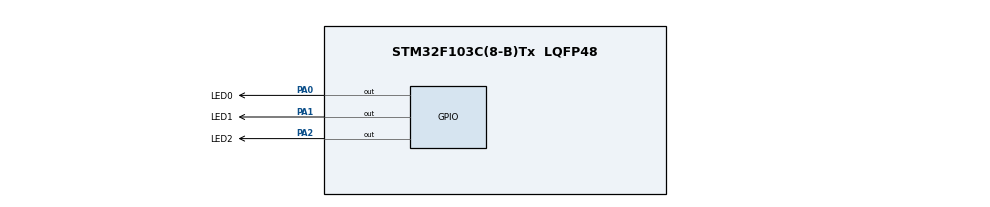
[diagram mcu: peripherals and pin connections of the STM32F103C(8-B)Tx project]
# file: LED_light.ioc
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Mcu.Family=STM32F1
Mcu.Name=STM32F103C(8-B)Tx
Mcu.Package=LQFP48
NVIC.PriorityGroup=NVIC_PRIORITYGROUP_4
PA0-WKUP.GPIO_Label=LED0
PA0-WKUP.Signal=GPIO_Output
PA1.GPIO_Label=LED1
PA1.Signal=GPIO_Output
PA13.Mode=Serial_Wire
PA13.Signal=SYS_JTMS-SWDIO
PA14.Mode=Serial_Wire
PA14.Signal=SYS_JTCK-SWCLK
PA2.GPIO_Label=LED2
PA2.Signal=GPIO_Output
PD0-OSC_IN.Mode=HSE-External-Oscillator
PD0-OSC_IN.Signal=RCC_OSC_IN
PD1-OSC_OUT.Mode=HSE-External-Oscillator
PD1-OSC_OUT.Signal=RCC_OSC_OUT
ProjectManager.HeapSize=0x200
ProjectManager.StackSize=0x400
ProjectManager.TargetToolchain=CMake
RCC.APB1Freq_Value=8000000
RCC.APB2Freq_Value=8000000
board=custom

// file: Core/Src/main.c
/* USER CODE BEGIN Header */
/**
  ******************************************************************************
  * @file           : main.c
  * @brief          : Main program body
  ******************************************************************************
  * @attention
  *
  * Copyright (c) 2026 STMicroelectronics.
  * All rights reserved.
  *
  * This software is licensed under terms that can be found in the LICENSE file
  * in the root directory of this software component.
  * If no LICENSE file comes with this software, it is provided AS-IS.
  *
  ******************************************************************************
  */
/* USER CODE END Header */
#include "main.h"

/* USER CODE BEGIN PD */
#define LED_NUM         3U     /* 三个灯：PA0/PA1/PA2 */
#define LED_DELAY_MS    500U   /* 每步停留 500ms，*/
#define LED_ACTIVE_LOW  1      /* 1=低电平点亮；0=高电平点亮 */
/* USER CODE END PD */

/* USER CODE BEGIN PV */
static const uint16_t      led_pin [LED_NUM] = { LED0_Pin,       LED1_Pin,       LED2_Pin       };
static GPIO_TypeDef *const led_port[LED_NUM] = { LED0_GPIO_Port, LED1_GPIO_Port, LED2_GPIO_Port };

static uint32_t led_last_tick = 0U;
static uint8_t  led_index     = 0U;
/* USER CODE END PV */

void SystemClock_Config(void);
static void MX_GPIO_Init(void);

/* USER CODE BEGIN 0 */
/** @brief 点亮第 idx 个 LED（按 LED_ACTIVE_LOW 自动取电平） */
static void Led_On(uint8_t idx)
{
  HAL_GPIO_WritePin(led_port[idx], led_pin[idx],
                    LED_ACTIVE_LOW ? GPIO_PIN_RESET : GPIO_PIN_SET);
}

/** @brief 熄灭第 idx 个 LED */
static void Led_Off(uint8_t idx)
{
  HAL_GPIO_WritePin(led_port[idx], led_pin[idx],
                    LED_ACTIVE_LOW ? GPIO_PIN_SET : GPIO_PIN_RESET);
}

/** @brief 全部熄灭 */
static void Led_AllOff(void)
{
  for (uint8_t i = 0U; i < LED_NUM; i++)
  {
    Led_Off(i);
  }
}
/* USER CODE END 0 */

int main(void)
{

  /* MCU Configuration--------------------------------------------------------*/

  /* Reset of all peripherals, Initializes the Flash interface and the Systick. */
  HAL_Init();

  /* Configure the system clock */
  SystemClock_Config();

  /* Initialize all configured peripherals */
  MX_GPIO_Init();
  /* USER CODE BEGIN 2 */
  Led_AllOff();

  Led_On(0);                 /* 上电先亮 PA0 */
  led_index     = 1U;        /* 下一个轮到 1 */
  led_last_tick = HAL_GetTick();
  /* USER CODE END 2 */

  /* Infinite loop */
  while (1) {

    /* USER CODE BEGIN 3 */
    for (uint8_t i = 0U; i < LED_NUM; i++)
    {

      if ((HAL_GetTick() - led_last_tick) >= LED_DELAY_MS)
      {
        led_last_tick += LED_DELAY_MS;

        Led_AllOff();
        Led_On(led_index);
        led_index = (uint8_t)((led_index + 1U) % LED_NUM);   /* 0→1→2→0 */
      }

    }
  }
  /* USER CODE END 3 */
}

void SystemClock_Config(void)
{
  RCC_OscInitTypeDef RCC_OscInitStruct = {0};
  RCC_ClkInitTypeDef RCC_ClkInitStruct = {0};

  /** Initializes the RCC Oscillators according to the specified parameters
  * in the RCC_OscInitTypeDef structure.
  */
  RCC_OscInitStruct.OscillatorType = RCC_OSCILLATORTYPE_HSI;
  RCC_OscInitStruct.HSIState = RCC_HSI_ON;
  RCC_OscInitStruct.HSICalibrationValue = RCC_HSICALIBRATION_DEFAULT;
  RCC_OscInitStruct.PLL.PLLState = RCC_PLL_NONE;
  if (HAL_RCC_OscConfig(&RCC_OscInitStruct) != HAL_OK)
  {
    Error_Handler();
  }

  /** Initializes the CPU, AHB and APB buses clocks
  */
  RCC_ClkInitStruct.ClockType = RCC_CLOCKTYPE_HCLK|RCC_CLOCKTYPE_SYSCLK
                              |RCC_CLOCKTYPE_PCLK1|RCC_CLOCKTYPE_PCLK2;
  RCC_ClkInitStruct.SYSCLKSource = RCC_SYSCLKSOURCE_HSI;
  RCC_ClkInitStruct.AHBCLKDivider = RCC_SYSCLK_DIV1;
  RCC_ClkInitStruct.APB1CLKDivider = RCC_HCLK_DIV1;
  RCC_ClkInitStruct.APB2CLKDivider = RCC_HCLK_DIV1;

  if (HAL_RCC_ClockConfig(&RCC_ClkInitStruct, FLASH_LATENCY_0) != HAL_OK)
  {
    Error_Handler();
  }
}

static void MX_GPIO_Init(void)
{
  GPIO_InitTypeDef GPIO_InitStruct = {0};

  /* GPIO Ports Clock Enable */
  __HAL_RCC_GPIOD_CLK_ENABLE();
  __HAL_RCC_GPIOA_CLK_ENABLE();

  /*Configure GPIO pin Output Level */
  HAL_GPIO_WritePin(GPIOA, LED0_Pin|LED1_Pin|LED2_Pin, GPIO_PIN_RESET);

  /*Configure GPIO pins : LED0_Pin LED1_Pin LED2_Pin */
  GPIO_InitStruct.Pin = LED0_Pin|LED1_Pin|LED2_Pin;
  GPIO_InitStruct.Mode = GPIO_MODE_OUTPUT_PP;
  GPIO_InitStruct.Pull = GPIO_NOPULL;
  GPIO_InitStruct.Speed = GPIO_SPEED_FREQ_LOW;
  HAL_GPIO_Init(GPIOA, &GPIO_InitStruct);

}

void Error_Handler(void) {
  __disable_irq();
  while (1)
  {
  }
}
